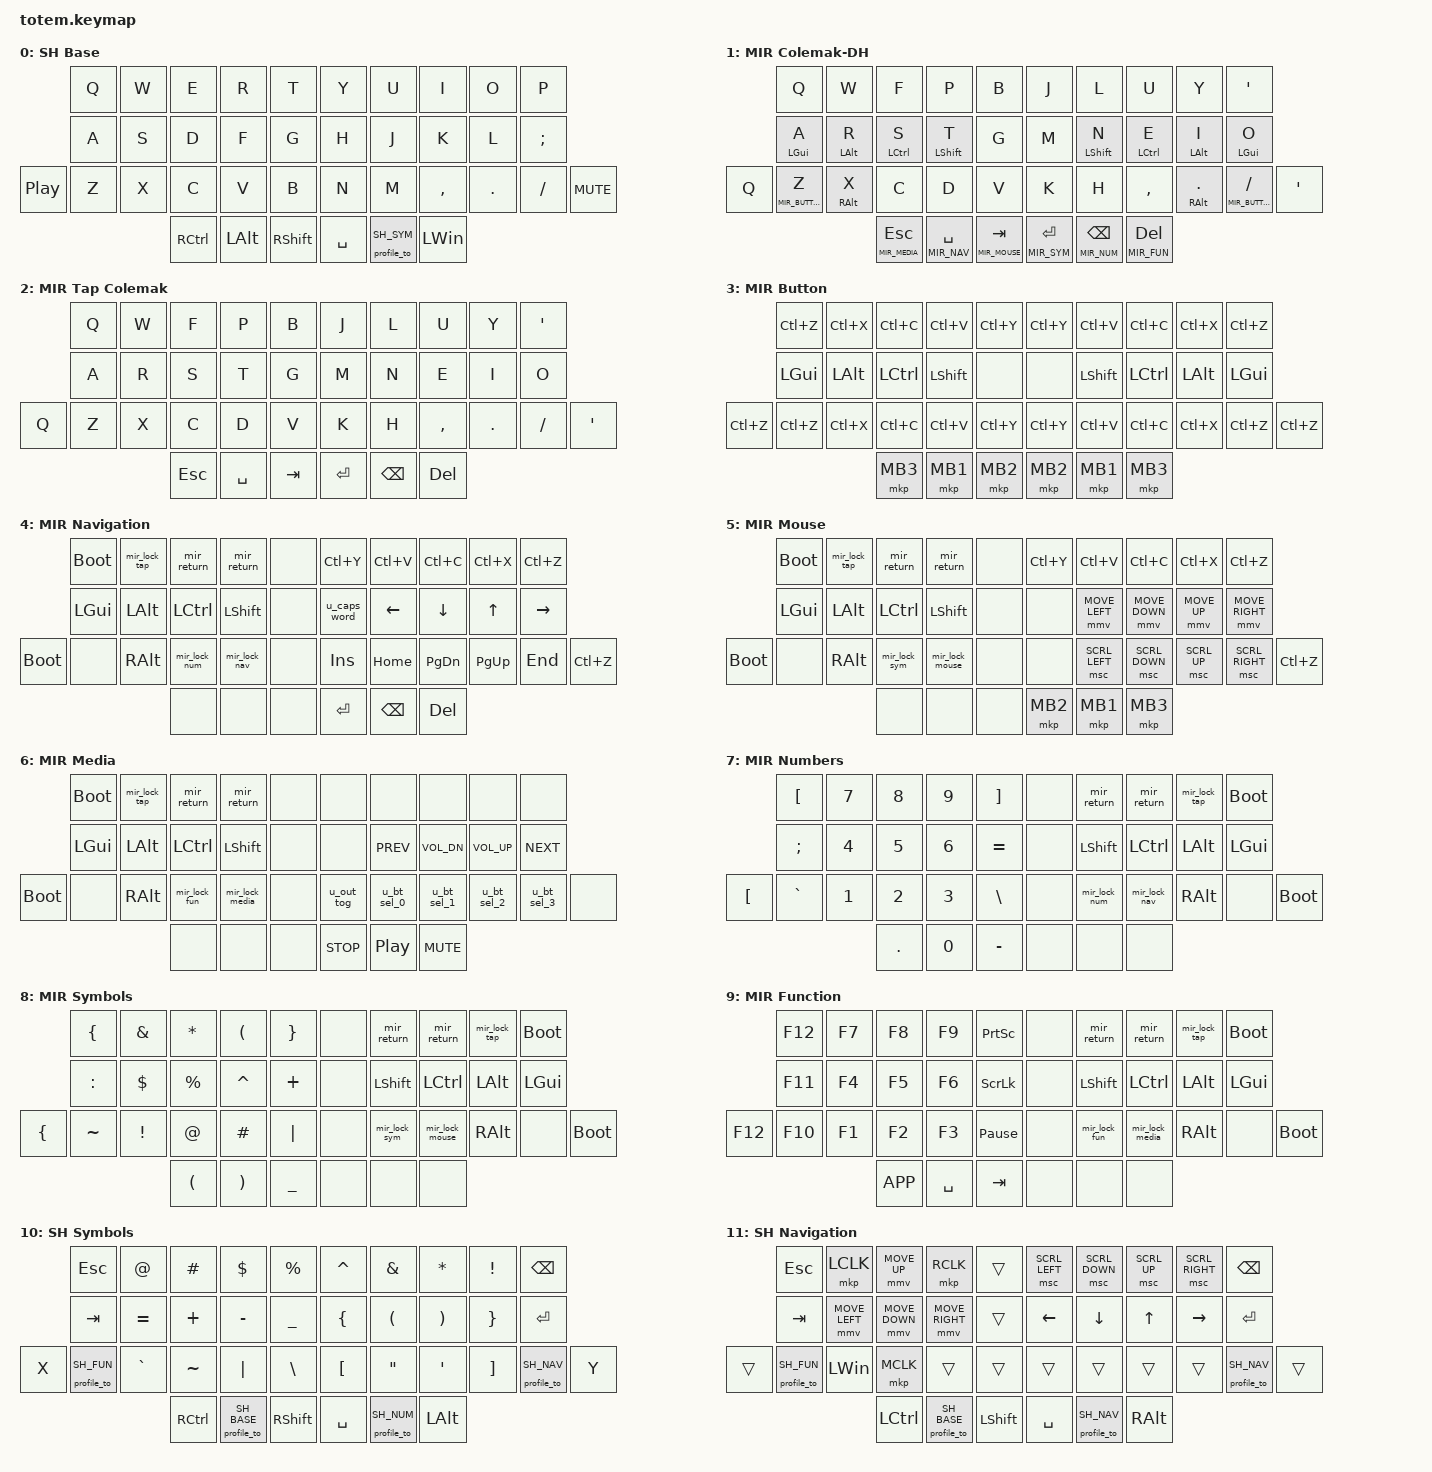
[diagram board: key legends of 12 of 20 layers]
// Generated by scripts/generate-keymap.mjs from sources/.
// Miryoku: Copyright 2022 Manna Harbour; Shamal: ShamalLakshan.
// See docs/studio-profiles.md for provenance and TOTEM adaptations.

#define ZMK_POINTING_DEFAULT_MOVE_VAL 1250
#define ZMK_POINTING_DEFAULT_SCRL_VAL 100
#include <behaviors.dtsi>
#include <dt-bindings/zmk/keys.h>
#include <dt-bindings/zmk/bt.h>
#include <dt-bindings/zmk/outputs.h>
#include <dt-bindings/zmk/pointing.h>
#include <totem_profiles.h>

&mmv { acceleration-exponent = <1>; time-to-max-speed-ms = <1500>; delay-ms = <0>; };
&caps_word { continue-list = <UNDERSCORE MINUS>; };

/ {
    behaviors {
        profile_to: profile_to {
            compatible = "roosmsg,profile-to";
            display-name = "Profile: To Layer";
            #binding-cells = <1>;
        };
        miryoku_mt: miryoku_mt {
            compatible = "zmk,behavior-hold-tap";
            display-name = "Miryoku Mod Tap";
            #binding-cells = <2>;
            tapping-term-ms = <200>;
            flavor = "tap-preferred";
            bindings = <&kp>, <&kp>;
        };
        miryoku_lt: miryoku_lt {
            compatible = "zmk,behavior-hold-tap";
            display-name = "Miryoku Layer Tap";
            #binding-cells = <2>;
            tapping-term-ms = <200>;
            flavor = "tap-preferred";
            bindings = <&mo>, <&kp>;
        };
        u_caps_word: u_caps_word {
            compatible = "zmk,behavior-mod-morph";
            #binding-cells = <0>;
            bindings = <&caps_word>, <&kp CAPS>;
            mods = <(MOD_LSFT|MOD_RSFT)>;
        };
        u_out_tog: u_out_tog {
            compatible = "zmk,behavior-mod-morph";
            #binding-cells = <0>;
            bindings = <&out OUT_TOG>, <&out OUT_USB>;
            mods = <(MOD_LSFT|MOD_RSFT)>;
        };
        u_bt_sel_0: u_bt_sel_0 {
            compatible = "zmk,behavior-mod-morph";
            #binding-cells = <0>;
            bindings = <&bt BT_SEL 0>, <&bt_clear_0>;
            mods = <(MOD_LSFT|MOD_RSFT)>;
        };
        u_bt_sel_1: u_bt_sel_1 {
            compatible = "zmk,behavior-mod-morph";
            #binding-cells = <0>;
            bindings = <&bt BT_SEL 1>, <&bt_clear_1>;
            mods = <(MOD_LSFT|MOD_RSFT)>;
        };
        u_bt_sel_2: u_bt_sel_2 {
            compatible = "zmk,behavior-mod-morph";
            #binding-cells = <0>;
            bindings = <&bt BT_SEL 2>, <&bt_clear_2>;
            mods = <(MOD_LSFT|MOD_RSFT)>;
        };
        u_bt_sel_3: u_bt_sel_3 {
            compatible = "zmk,behavior-mod-morph";
            #binding-cells = <0>;
            bindings = <&bt BT_SEL 3>, <&bt_clear_3>;
            mods = <(MOD_LSFT|MOD_RSFT)>;
        };
        u_bt_sel_4: u_bt_sel_4 {
            compatible = "zmk,behavior-mod-morph";
            #binding-cells = <0>;
            bindings = <&bt BT_SEL 4>, <&bt_clear_4>;
            mods = <(MOD_LSFT|MOD_RSFT)>;
        };
        mir_return: mir_return {
            compatible = "zmk,behavior-tap-dance";
            #binding-cells = <0>;
            tapping-term-ms = <200>;
            bindings = <&none>, <&profile_to PROFILE_RETURN>;
        };
        mir_lock_tap: mir_lock_tap {
            compatible = "zmk,behavior-tap-dance";
            #binding-cells = <0>;
            tapping-term-ms = <200>;
            bindings = <&none>, <&profile_to MIR_TAP>;
        };
        mir_lock_button: mir_lock_button {
            compatible = "zmk,behavior-tap-dance";
            #binding-cells = <0>;
            tapping-term-ms = <200>;
            bindings = <&none>, <&profile_to MIR_BUTTON>;
        };
        mir_lock_nav: mir_lock_nav {
            compatible = "zmk,behavior-tap-dance";
            #binding-cells = <0>;
            tapping-term-ms = <200>;
            bindings = <&none>, <&profile_to MIR_NAV>;
        };
        mir_lock_mouse: mir_lock_mouse {
            compatible = "zmk,behavior-tap-dance";
            #binding-cells = <0>;
            tapping-term-ms = <200>;
            bindings = <&none>, <&profile_to MIR_MOUSE>;
        };
        mir_lock_media: mir_lock_media {
            compatible = "zmk,behavior-tap-dance";
            #binding-cells = <0>;
            tapping-term-ms = <200>;
            bindings = <&none>, <&profile_to MIR_MEDIA>;
        };
        mir_lock_num: mir_lock_num {
            compatible = "zmk,behavior-tap-dance";
            #binding-cells = <0>;
            tapping-term-ms = <200>;
            bindings = <&none>, <&profile_to MIR_NUM>;
        };
        mir_lock_sym: mir_lock_sym {
            compatible = "zmk,behavior-tap-dance";
            #binding-cells = <0>;
            tapping-term-ms = <200>;
            bindings = <&none>, <&profile_to MIR_SYM>;
        };
        mir_lock_fun: mir_lock_fun {
            compatible = "zmk,behavior-tap-dance";
            #binding-cells = <0>;
            tapping-term-ms = <200>;
            bindings = <&none>, <&profile_to MIR_FUN>;
        };
        s2_sym_num: s2_sym_num {
            compatible = "zmk,behavior-tap-dance";
            display-name = "S2 Symbols / Numpad Lock";
            #binding-cells = <0>;
            tapping-term-ms = <300>;
            bindings = <&mo S2_SYMBOLS>, <&tog S2_NUM>;
        };
        s2_erase: s2_erase {
            compatible = "zmk,behavior-hold-tap";
            display-name = "S2 Erase (tap / hold)";
            #binding-cells = <2>;
            flavor = "tap-preferred";
            tapping-term-ms = <350>;
            quick-tap-ms = <250>;
            bindings = <&kp>, <&kp>;
        };
        s2_bspc_del: s2_bspc_del {
            compatible = "zmk,behavior-mod-morph";
            display-name = "S2 Backspace / Ctrl: Delete";
            #binding-cells = <0>;
            bindings = <&s2_erase LC(BSPC) BSPC>, <&s2_erase LC(DEL) DEL>;
            mods = <(MOD_LCTL|MOD_RCTL)>;
        };
    };
    conditional_layers {
        compatible = "zmk,conditional-layers";
        s2_settings_tri_layer {
            if-layers = <S2_FKEYS S2_NUM>;
            then-layer = <S2_SETTINGS>;
        };
    };
    macros {
        bt_clear_0: bt_clear_0 {
            compatible = "zmk,behavior-macro";
            #binding-cells = <0>;
            wait-ms = <0>;
            bindings = <&bt BT_SEL 0 &bt BT_CLR>;
        };
        bt_clear_1: bt_clear_1 {
            compatible = "zmk,behavior-macro";
            #binding-cells = <0>;
            wait-ms = <0>;
            bindings = <&bt BT_SEL 1 &bt BT_CLR>;
        };
        bt_clear_2: bt_clear_2 {
            compatible = "zmk,behavior-macro";
            #binding-cells = <0>;
            wait-ms = <0>;
            bindings = <&bt BT_SEL 2 &bt BT_CLR>;
        };
        bt_clear_3: bt_clear_3 {
            compatible = "zmk,behavior-macro";
            #binding-cells = <0>;
            wait-ms = <0>;
            bindings = <&bt BT_SEL 3 &bt BT_CLR>;
        };
        bt_clear_4: bt_clear_4 {
            compatible = "zmk,behavior-macro";
            #binding-cells = <0>;
            wait-ms = <0>;
            bindings = <&bt BT_SEL 4 &bt BT_CLR>;
        };
    };
    combos {
        compatible = "zmk,combos";
        sh_combo_enter {
            bindings = <&kp ENTER>;
            key-positions = <16 17>;
            layers = <SH_BASE>;
            timeout-ms = <50>;
                };
        sh_combo_tab {
            bindings = <&kp TAB>;
            key-positions = <0 1>;
            require-prior-idle-ms = <50>;
            layers = <SH_BASE>;
                };
        sh_combo_ctrl_backspace {
            bindings = <&kp RC(BACKSPACE)>;
            key-positions = <23 24>;
            timeout-ms = <50>;
            layers = <SH_BASE>;
                };
        sh_combo_quote {
            bindings = <&kp SINGLE_QUOTE>;
            key-positions = <29 28>;
            timeout-ms = <50>;
            layers = <SH_BASE>;
                };
        sh_combo_ctrl_shift {
            bindings = <&kp LC(LEFT_SHIFT)>;
            key-positions = <21 22>;
            timeout-ms = <50>;
            layers = <SH_BASE>;
                };
        sh_combo_backspace {
            bindings = <&kp BACKSPACE>;
            key-positions = <12 13>;
            timeout-ms = <50>;
            layers = <SH_BASE>;
                };
        sh_combo_alt_shift {
            bindings = <&kp LA(LEFT_SHIFT)>;
            key-positions = <13 12>;
            timeout-ms = <50>;
            layers = <SH_NUM>;
                };
        s2_combo_enter {
            bindings = <&kp ENTER>;
            key-positions = <16 17>;
            layers = <S2_BASE>;
            timeout-ms = <50>;
                };
        s2_combo_tab {
            bindings = <&kp TAB>;
            key-positions = <0 1>;
            require-prior-idle-ms = <50>;
            layers = <S2_BASE>;
                };
        s2_combo_ctrl_backspace {
            bindings = <&kp RC(BACKSPACE)>;
            key-positions = <23 24>;
            timeout-ms = <50>;
            layers = <S2_BASE>;
                };
        s2_combo_quote {
            bindings = <&kp SINGLE_QUOTE>;
            key-positions = <29 28>;
            timeout-ms = <50>;
            layers = <S2_BASE>;
                };
        s2_combo_ctrl_shift {
            bindings = <&kp LC(LEFT_SHIFT)>;
            key-positions = <21 22>;
            timeout-ms = <50>;
            layers = <S2_BASE>;
                };
        s2_combo_backspace {
            bindings = <&s2_erase LC(BSPC) BSPC>;
            key-positions = <12 13>;
            timeout-ms = <50>;
            layers = <S2_BASE>;
                };
    };
    keymap {
        compatible = "zmk,keymap";
        sh_base {
            display-name = "SH Base";
            bindings = <
                                          &kp Q                         &kp W                         &kp E                         &kp R                         &kp T                         &kp Y                         &kp U                         &kp I                         &kp O                         &kp P
                                          &kp A                         &kp S                         &kp D                         &kp F                         &kp G                         &kp H                         &kp J                         &kp K                         &kp L                         &kp SEMICOLON
            &kp C_PLAY_PAUSE              &kp Z                         &kp X                         &kp C                         &kp V                         &kp B                         &kp N                         &kp M                         &kp COMMA                     &kp DOT                       &kp FSLH                      &kp C_MUTE
                                                                                                      &kp RCTRL                     &kp LEFT_ALT                  &kp RIGHT_SHIFT               &kp SPACE                     &profile_to SH_SYM            &kp LEFT_WIN
            >;
        };

        mir_colemak {
            display-name = "MIR Colemak-DH";
            bindings = <
                                          &kp Q                         &kp W                         &kp F                         &kp P                         &kp B                         &kp J                         &kp L                         &kp U                         &kp Y                         &kp SQT
                                          &miryoku_mt LGUI A            &miryoku_mt LALT R            &miryoku_mt LCTRL S           &miryoku_mt LSHFT T           &kp G                         &kp M                         &miryoku_mt LSHFT N           &miryoku_mt LCTRL E           &miryoku_mt LALT I            &miryoku_mt LGUI O
            &kp Q                         &miryoku_lt MIR_BUTTON Z      &miryoku_mt RALT X            &kp C                         &kp D                         &kp V                         &kp K                         &kp H                         &kp COMMA                     &miryoku_mt RALT DOT          &miryoku_lt MIR_BUTTON SLASH  &kp SQT
                                                                                                      &miryoku_lt MIR_MEDIA ESC     &miryoku_lt MIR_NAV SPACE     &miryoku_lt MIR_MOUSE TAB     &miryoku_lt MIR_SYM RET       &miryoku_lt MIR_NUM BSPC      &miryoku_lt MIR_FUN DEL
            >;
        };

        mir_tap {
            display-name = "MIR Tap Colemak";
            bindings = <
                                          &kp Q                         &kp W                         &kp F                         &kp P                         &kp B                         &kp J                         &kp L                         &kp U                         &kp Y                         &kp SQT
                                          &kp A                         &kp R                         &kp S                         &kp T                         &kp G                         &kp M                         &kp N                         &kp E                         &kp I                         &kp O
            &kp Q                         &kp Z                         &kp X                         &kp C                         &kp D                         &kp V                         &kp K                         &kp H                         &kp COMMA                     &kp DOT                       &kp SLASH                     &kp SQT
                                                                                                      &kp ESC                       &kp SPACE                     &kp TAB                       &kp RET                       &kp BSPC                      &kp DEL
            >;
        };

        mir_button {
            display-name = "MIR Button";
            bindings = <
                                          &kp LC(Z)                     &kp LC(X)                     &kp LC(C)                     &kp LC(V)                     &kp LC(Y)                     &kp LC(Y)                     &kp LC(V)                     &kp LC(C)                     &kp LC(X)                     &kp LC(Z)
                                          &kp LGUI                      &kp LALT                      &kp LCTRL                     &kp LSHFT                     &none                         &none                         &kp LSHFT                     &kp LCTRL                     &kp LALT                      &kp LGUI
            &kp LC(Z)                     &kp LC(Z)                     &kp LC(X)                     &kp LC(C)                     &kp LC(V)                     &kp LC(Y)                     &kp LC(Y)                     &kp LC(V)                     &kp LC(C)                     &kp LC(X)                     &kp LC(Z)                     &kp LC(Z)
                                                                                                      &mkp MB3                      &mkp MB1                      &mkp MB2                      &mkp MB2                      &mkp MB1                      &mkp MB3
            >;
        };

        mir_nav {
            display-name = "MIR Navigation";
            bindings = <
                                          &bootloader                   &mir_lock_tap                 &mir_return                   &mir_return                   &none                         &kp LC(Y)                     &kp LC(V)                     &kp LC(C)                     &kp LC(X)                     &kp LC(Z)
                                          &kp LGUI                      &kp LALT                      &kp LCTRL                     &kp LSHFT                     &none                         &u_caps_word                  &kp LEFT                      &kp DOWN                      &kp UP                        &kp RIGHT
            &bootloader                   &none                         &kp RALT                      &mir_lock_num                 &mir_lock_nav                 &none                         &kp INS                       &kp HOME                      &kp PG_DN                     &kp PG_UP                     &kp END                       &kp LC(Z)
                                                                                                      &none                         &none                         &none                         &kp RET                       &kp BSPC                      &kp DEL
            >;
        };

        mir_mouse {
            display-name = "MIR Mouse";
            bindings = <
                                          &bootloader                   &mir_lock_tap                 &mir_return                   &mir_return                   &none                         &kp LC(Y)                     &kp LC(V)                     &kp LC(C)                     &kp LC(X)                     &kp LC(Z)
                                          &kp LGUI                      &kp LALT                      &kp LCTRL                     &kp LSHFT                     &none                         &none                         &mmv MOVE_LEFT                &mmv MOVE_DOWN                &mmv MOVE_UP                  &mmv MOVE_RIGHT
            &bootloader                   &none                         &kp RALT                      &mir_lock_sym                 &mir_lock_mouse               &none                         &none                         &msc SCRL_LEFT                &msc SCRL_DOWN                &msc SCRL_UP                  &msc SCRL_RIGHT               &kp LC(Z)
                                                                                                      &none                         &none                         &none                         &mkp MB2                      &mkp MB1                      &mkp MB3
            >;
        };

        mir_media {
            display-name = "MIR Media";
            bindings = <
                                          &bootloader                   &mir_lock_tap                 &mir_return                   &mir_return                   &none                         &none                         &none                         &none                         &none                         &none
                                          &kp LGUI                      &kp LALT                      &kp LCTRL                     &kp LSHFT                     &none                         &none                         &kp C_PREV                    &kp C_VOL_DN                  &kp C_VOL_UP                  &kp C_NEXT
            &bootloader                   &none                         &kp RALT                      &mir_lock_fun                 &mir_lock_media               &none                         &u_out_tog                    &u_bt_sel_0                   &u_bt_sel_1                   &u_bt_sel_2                   &u_bt_sel_3                   &none
                                                                                                      &none                         &none                         &none                         &kp C_STOP                    &kp C_PP                      &kp C_MUTE
            >;
        };

        mir_num {
            display-name = "MIR Numbers";
            bindings = <
                                          &kp LBKT                      &kp N7                        &kp N8                        &kp N9                        &kp RBKT                      &none                         &mir_return                   &mir_return                   &mir_lock_tap                 &bootloader
                                          &kp SEMI                      &kp N4                        &kp N5                        &kp N6                        &kp EQUAL                     &none                         &kp LSHFT                     &kp LCTRL                     &kp LALT                      &kp LGUI
            &kp LBKT                      &kp GRAVE                     &kp N1                        &kp N2                        &kp N3                        &kp BSLH                      &none                         &mir_lock_num                 &mir_lock_nav                 &kp RALT                      &none                         &bootloader
                                                                                                      &kp DOT                       &kp N0                        &kp MINUS                     &none                         &none                         &none
            >;
        };

        mir_sym {
            display-name = "MIR Symbols";
            bindings = <
                                          &kp LBRC                      &kp AMPS                      &kp ASTRK                     &kp LPAR                      &kp RBRC                      &none                         &mir_return                   &mir_return                   &mir_lock_tap                 &bootloader
                                          &kp COLON                     &kp DLLR                      &kp PRCNT                     &kp CARET                     &kp PLUS                      &none                         &kp LSHFT                     &kp LCTRL                     &kp LALT                      &kp LGUI
            &kp LBRC                      &kp TILDE                     &kp EXCL                      &kp AT                        &kp HASH                      &kp PIPE                      &none                         &mir_lock_sym                 &mir_lock_mouse               &kp RALT                      &none                         &bootloader
                                                                                                      &kp LPAR                      &kp RPAR                      &kp UNDER                     &none                         &none                         &none
            >;
        };

        mir_fun {
            display-name = "MIR Function";
            bindings = <
                                          &kp F12                       &kp F7                        &kp F8                        &kp F9                        &kp PSCRN                     &none                         &mir_return                   &mir_return                   &mir_lock_tap                 &bootloader
                                          &kp F11                       &kp F4                        &kp F5                        &kp F6                        &kp SLCK                      &none                         &kp LSHFT                     &kp LCTRL                     &kp LALT                      &kp LGUI
            &kp F12                       &kp F10                       &kp F1                        &kp F2                        &kp F3                        &kp PAUSE_BREAK               &none                         &mir_lock_fun                 &mir_lock_media               &kp RALT                      &none                         &bootloader
                                                                                                      &kp K_APP                     &kp SPACE                     &kp TAB                       &none                         &none                         &none
            >;
        };

        sh_symbol {
            display-name = "SH Symbols";
            bindings = <
                                          &kp ESC                       &kp AT_SIGN                   &kp HASH                      &kp DOLLAR                    &kp PERCENT                   &kp CARET                     &kp AMPERSAND                 &kp ASTERISK                  &kp EXCLAMATION               &kp BACKSPACE
                                          &kp TAB                       &kp EQUAL                     &kp PLUS                      &kp MINUS                     &kp UNDERSCORE                &kp LEFT_BRACE                &kp LEFT_PARENTHESIS          &kp RIGHT_PARENTHESIS         &kp RIGHT_BRACE               &kp ENTER
            &kp X                         &profile_to SH_FUN            &kp GRAVE                     &kp TILDE                     &kp PIPE                      &kp BACKSLASH                 &kp LEFT_BRACKET              &kp DOUBLE_QUOTES             &kp SINGLE_QUOTE              &kp RIGHT_BRACKET             &profile_to SH_NAV            &kp Y
                                                                                                      &kp RCTRL                     &profile_to SH_BASE           &kp RIGHT_SHIFT               &kp SPACE                     &profile_to SH_NUM            &kp LEFT_ALT
            >;
        };

        sh_nav {
            display-name = "SH Navigation";
            bindings = <
                                          &kp ESCAPE                    &mkp LCLK                     &mmv MOVE_UP                  &mkp RCLK                     &trans                        &msc SCRL_LEFT                &msc SCRL_DOWN                &msc SCRL_UP                  &msc SCRL_RIGHT               &kp BACKSPACE
                                          &kp TAB                       &mmv MOVE_LEFT                &mmv MOVE_DOWN                &mmv MOVE_RIGHT               &trans                        &kp LEFT                      &kp DOWN                      &kp UP_ARROW                  &kp RIGHT                     &kp ENTER
            &trans                        &profile_to SH_FUN            &kp LEFT_WIN                  &mkp MCLK                     &trans                        &trans                        &trans                        &trans                        &trans                        &trans                        &profile_to SH_NAV            &trans
                                                                                                      &kp LCTRL                     &profile_to SH_BASE           &kp LEFT_SHIFT                &kp SPACE                     &profile_to SH_NAV            &kp RIGHT_ALT
            >;
        };

        sh_num {
            display-name = "SH Numbers";
            bindings = <
                                          &kp ESCAPE                    &kp CAPS                      &kp SCROLLLOCK                &kp KP_NUMLOCK                &kp PG_UP                     &kp HOME                      &kp NUMBER_7                  &kp NUMBER_8                  &kp NUMBER_9                  &kp BACKSPACE
                                          &kp LS(TAB)                   &kp LS(K_CUT)                 &kp LS(K_COPY)                &kp LS(K_PASTE)               &kp LS(PG_DN)                 &kp END                       &kp NUMBER_4                  &kp NUMBER_5                  &kp NUMBER_6                  &kp ENTER
            &trans                        &profile_to SH_FUN            &kp INSERT                    &kp K_UNDO                    &kp K_REDO                    &kp DELETE                    &kp NUMBER_0                  &kp NUMBER_1                  &kp NUMBER_2                  &kp NUMBER_3                  &profile_to SH_NAV            &trans
                                                                                                      &kp RCTRL                     &profile_to SH_BASE           &kp LEFT_SHIFT                &kp SPACE                     &profile_to SH_SYM            &kp LEFT_ALT
            >;
        };

        sh_function {
            display-name = "SH Function";
            bindings = <
                                          &kp ESCAPE                    &kp C_BRIGHTNESS_DEC          &trans                        &kp C_BRIGHTNESS_INC          &trans                        &kp F9                        &kp F10                       &kp F11                       &kp F12                       &kp BACKSPACE
                                          &kp TAB                       &kp C_PREVIOUS                &kp C_PLAY_PAUSE              &kp C_NEXT                    &trans                        &kp F5                        &kp F6                        &kp F7                        &kp F8                        &kp ENTER
            &trans                        &profile_to SH_FUN            &trans                        &kp C_MUTE                    &trans                        &profile_to SH_SETTINGS       &kp F1                        &kp F2                        &kp F3                        &kp F4                        &profile_to SH_NAV            &trans
                                                                                                      &kp LCTRL                     &profile_to SH_BASE           &kp LEFT_SHIFT                &kp SPACE                     &profile_to SH_NUM            &kp RIGHT_ALT
            >;
        };

        sh_settings {
            display-name = "SH Settings";
            bindings = <
                                          &kp ESCAPE                    &bt BT_SEL 0                  &bt BT_SEL 1                  &bt BT_SEL 2                  &bt BT_CLR                    &trans                        &trans                        &trans                        &trans                        &kp BACKSPACE
                                          &kp TAB                       &trans                        &bt BT_NXT                    &bt BT_PRV                    &bt BT_CLR_ALL                &trans                        &bootloader                   &studio_unlock                &sys_reset                    &kp ENTER
            &trans                        &profile_to SH_FUN            &trans                        &out OUT_BLE                  &out OUT_USB                  &profile_to SH_SETTINGS       &trans                        &trans                        &trans                        &trans                        &profile_to SH_NAV            &trans
                                                                                                      &kp LCTRL                     &profile_to SH_BASE           &kp LEFT_SHIFT                &kp SPACE                     &profile_to SH_NUM            &kp RIGHT_ALT
            >;
        };

        s2_base {
            display-name = "S2 Base";
            bindings = <
                                          &kp Q                         &kp W                         &kp E                         &kp R                         &kp T                         &kp Y                         &kp U                         &kp I                         &kp O                         &s2_bspc_del
                                          &kp A                         &kp S                         &kp D                         &kp F                         &kp G                         &kp H                         &kp J                         &kp K                         &kp L                         &kp P
            &kp LSHIFT                    &kp Z                         &kp X                         &kp C                         &kp V                         &kp B                         &kp N                         &kp M                         &kp COMMA                     &kp DOT                       &kp FSLH                      &mt RSHIFT SEMI
                                                                                                      &kp LGUI                      &kp LCTRL                     &lt S2_FKEYS ENTER            &lt S2_NUM SPACE              &s2_sym_num                   &kp LALT
            >;
        };

        s2_symbols {
            display-name = "S2 Symbols";
            bindings = <
                                          &kp N1                        &kp N2                        &kp N3                        &kp N4                        &kp N5                        &kp N6                        &kp N7                        &kp N8                        &kp N9                        &kp N0
                                          &kp EXCL                      &kp AT                        &kp HASH                      &kp DLLR                      &kp PRCNT                     &kp CARET                     &kp AMPERSAND                 &kp STAR                      &kp LPAR                      &kp RPAR
            &trans                        &kp LG(DOT)                   &kp LEFT_BRACE                &kp RIGHT_BRACE               &kp PIPE                      &kp EQUAL                     &kp MINUS                     &kp PLUS                      &kp LBKT                      &kp RBKT                      &kp BACKSLASH                 &kp UNDER
                                                                                                      &trans                        &trans                        &trans                        &trans                        &trans                        &kp DEL
            >;
        };

        s2_numpad {
            display-name = "S2 Number Pad";
            bindings = <
                                          &kp N1                        &kp N2                        &kp N3                        &kp N4                        &kp N5                        &kp N6                        &kp N7                        &kp N8                        &kp N9                        &kp N0
                                          &kp EXCL                      &kp AT                        &kp HASH                      &kp DLLR                      &kp PRCNT                     &kp CARET                     &kp N4                        &kp N5                        &mt LPAR N6                   &mt RPAR PLUS
            &kp MINUS                     &trans                        &kp LEFT_BRACE                &kp RIGHT_BRACE               &kp PIPE                      &kp EQUAL                     &kp PRCNT                     &kp N1                        &mt COMMA N2                  &mt DOT N3                    &kp KP_DIVIDE                 &kp KP_MULTIPLY
                                                                                                      &trans                        &trans                        &trans                        &trans                        &tog S2_NUM                   &kp N0
            >;
        };

        s2_fkeys {
            display-name = "S2 F-keys/Nav";
            bindings = <
                                          &kp F1                        &kp F2                        &kp F3                        &kp F4                        &kp F5                        &kp F6                        &kp F7                        &kp F8                        &kp F9                        &kp F10
                                          &kp LG(H)                     &trans                        &kp C_PREV                    &kp C_PP                      &kp C_NEXT                    &kp HOME                      &kp UP                        &kp END                       &kp LA(PSCRN)                 &kp PG_UP
            &kp ESC                       &kp F11                       &kp F12                       &kp C_VOL_DN                  &kp C_MUTE                    &kp C_VOL_UP                  &kp LEFT                      &kp DOWN                      &kp RIGHT                     &kp LG(LS(S))                 &kp PG_DN                     &kp LS(TAB)
                                                                                                      &trans                        &trans                        &trans                        &trans                        &trans                        &trans
            >;
        };

        s2_settings {
            display-name = "S2 Settings";
            bindings = <
                                          &bt BT_SEL 0                  &bt BT_SEL 1                  &bt BT_SEL 2                  &bt BT_SEL 3                  &bt BT_SEL 4                  &kp N6                        &kp N7                        &kp N8                        &kp N9                        &kp N0
                                          &trans                        &trans                        &trans                        &trans                        &trans                        &trans                        &kp N4                        &kp N5                        &kp N6                        &trans
            &out OUT_TOG                  &trans                        &bt BT_CLR                    &trans                        &trans                        &trans                        &trans                        &kp N1                        &kp N2                        &kp N3                        &trans                        &trans
                                                                                                      &trans                        &trans                        &trans                        &trans                        &trans                        &kp N0
            >;
        };
    };
};
